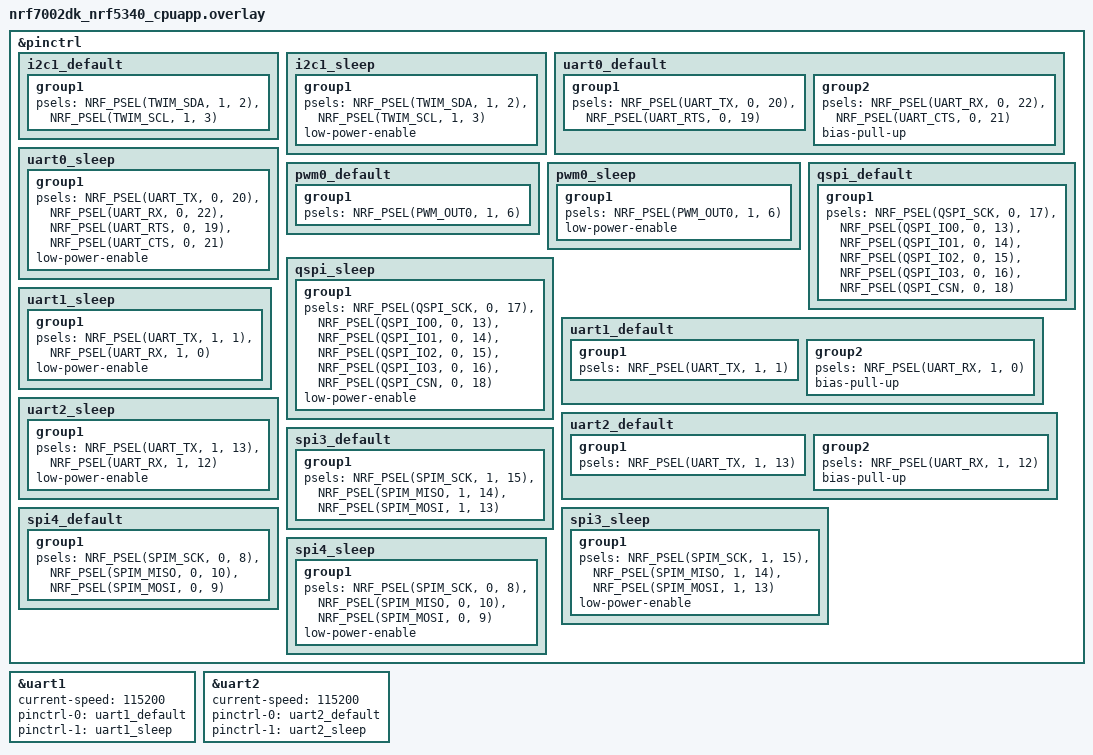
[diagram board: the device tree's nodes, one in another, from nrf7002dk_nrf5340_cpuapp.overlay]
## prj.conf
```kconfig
# Because we're not using console, and are using uart0 as hardware uart:
CONFIG_CONSOLE=n

# Logging
# CONFIG_PRINTK=y

CONFIG_UART_ASYNC_API=y
CONFIG_UART_INTERRUPT_DRIVEN=n

# So we can use k_malloc
CONFIG_HEAP_MEM_POOL_SIZE=2048
```

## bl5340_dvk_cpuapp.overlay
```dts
// Allow uart1 to be used as a normal UART instead of forwarding to network core for serial logging
/delete-node/ &gpio_fwd;


/ {
    chosen {
        /delete-property/ zephyr,keyboard-scan;
	};

    // aliases {
    //     /delete-property/ accel0;
    //     /delete-property/ bbram0;
    //     /delete-property/ kscan0;
    // };

    /delete-node/ aliases;

    /delete-node/ buttons;

    /delete-node/ leds;
};

// Just setting status of i2c1 to "disabled" doesn't work; causes error. Need to fully delete node.
/delete-node/ &i2c1;



&pinctrl {
    uart1_default: uart1_default {
		group1 {
			psels = <NRF_PSEL(UART_TX, 1, 1)>;
		};
		group2 {
			psels = <NRF_PSEL(UART_RX, 1, 0)>;
			bias-pull-up;
		};
	};

	uart1_sleep: uart1_sleep {
		group1 {
			psels = <NRF_PSEL(UART_TX, 1, 1)>,
				<NRF_PSEL(UART_RX, 1, 0)>;
			low-power-enable;
		};
	};

	uart2_default: uart2_default {
		group1 {
			psels = <NRF_PSEL(UART_TX, 1, 13)>;
		};
		group2 {
			psels = <NRF_PSEL(UART_RX, 1, 12)>;
			bias-pull-up;
		};
	};

	uart2_sleep: uart2_sleep {
		group1 {
			psels = <NRF_PSEL(UART_TX, 1, 13)>,
				<NRF_PSEL(UART_RX, 1, 12)>;
			low-power-enable;
		};
	};
};





&uart1 {
	status = "okay";
	current-speed = <115200>;
	pinctrl-0 = <&uart1_default>;
	pinctrl-1 = <&uart1_sleep>;
	pinctrl-names = "default", "sleep";
};

&uart2 {
	status = "okay";
	current-speed = <115200>;
	pinctrl-0 = <&uart2_default>;
	pinctrl-1 = <&uart2_sleep>;
	pinctrl-names = "default", "sleep";
};
```

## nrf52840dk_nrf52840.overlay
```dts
/ {
    chosen {
        /delete-property/ zephyr,console;
        /delete-property/ zephyr,shell-uart;
        /delete-property/ zephyr,uart-mcumgr;
        /delete-property/ zephyr,bt-mon-uart;
        /delete-property/ zephyr,bt-c2h-uart;
	};
};

&pinctrl {
    uart0_default: uart0_default {
		group1 {
			psels = <NRF_PSEL(UART_TX, 0, 28)>;
		};
		group2 {
			psels = <NRF_PSEL(UART_RX, 0, 30)>;
			bias-pull-up;
		};
	};

	uart0_sleep: uart0_sleep {
		group1 {
			psels = <NRF_PSEL(UART_TX, 0, 28)>,
				<NRF_PSEL(UART_RX, 0, 30)>;
			low-power-enable;
		};
	};

	uart1_default: uart1_default {
		group1 {
			psels = <NRF_PSEL(UART_TX, 0, 4)>;
            bias-pull-up;
		};
		group2 {
			psels = <NRF_PSEL(UART_RX, 0, 5)>;
			bias-pull-up;
		};
	};

	uart1_sleep: uart1_sleep {
		group1 {
			psels = <NRF_PSEL(UART_TX, 0, 4)>,
				<NRF_PSEL(UART_RX, 0, 5)>;
			low-power-enable;
		};
	};
};


&uart0 {
    compatible = "nordic,nrf-uarte";
	status = "okay";
    current-speed = <115200>;
	pinctrl-0 = <&uart0_default>;
	pinctrl-1 = <&uart0_sleep>;
	pinctrl-names = "default", "sleep";
};

&uart1 {
	status = "okay";
	current-speed = <9600>;
	pinctrl-0 = <&uart1_default>;
	pinctrl-1 = <&uart1_sleep>;
	pinctrl-names = "default", "sleep";
};
```

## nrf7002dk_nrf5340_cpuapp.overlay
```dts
// Allow uart1 to be used as a normal UART instead of forwarding to network core for serial logging
/delete-node/ &gpio_fwd;



&pinctrl {
	i2c1_default: i2c1_default {
		group1 {
			psels = <NRF_PSEL(TWIM_SDA, 1, 2)>,
				<NRF_PSEL(TWIM_SCL, 1, 3)>;
		};
	};

	i2c1_sleep: i2c1_sleep {
		group1 {
			psels = <NRF_PSEL(TWIM_SDA, 1, 2)>,
				<NRF_PSEL(TWIM_SCL, 1, 3)>;
			low-power-enable;
		};
	};

	uart0_default: uart0_default {
		group1 {
			psels = <NRF_PSEL(UART_TX, 0, 20)>,
				<NRF_PSEL(UART_RTS, 0, 19)>;
		};
		group2 {
			psels = <NRF_PSEL(UART_RX, 0, 22)>,
				<NRF_PSEL(UART_CTS, 0, 21)>;
			bias-pull-up;
		};
	};

	uart0_sleep: uart0_sleep {
		group1 {
			psels = <NRF_PSEL(UART_TX, 0, 20)>,
				<NRF_PSEL(UART_RX, 0, 22)>,
				<NRF_PSEL(UART_RTS, 0, 19)>,
				<NRF_PSEL(UART_CTS, 0, 21)>;
			low-power-enable;
		};
	};

	pwm0_default: pwm0_default {
		group1 {
			psels = <NRF_PSEL(PWM_OUT0, 1, 6)>;
		};
	};

	pwm0_sleep: pwm0_sleep {
		group1 {
			psels = <NRF_PSEL(PWM_OUT0, 1, 6)>;
			low-power-enable;
		};
	};

	qspi_default: qspi_default {
		group1 {
			psels = <NRF_PSEL(QSPI_SCK, 0, 17)>,
				<NRF_PSEL(QSPI_IO0, 0, 13)>,
				<NRF_PSEL(QSPI_IO1, 0, 14)>,
				<NRF_PSEL(QSPI_IO2, 0, 15)>,
				<NRF_PSEL(QSPI_IO3, 0, 16)>,
				<NRF_PSEL(QSPI_CSN, 0, 18)>;
		};
	};

	qspi_sleep: qspi_sleep {
		group1 {
			psels = <NRF_PSEL(QSPI_SCK, 0, 17)>,
				<NRF_PSEL(QSPI_IO0, 0, 13)>,
				<NRF_PSEL(QSPI_IO1, 0, 14)>,
				<NRF_PSEL(QSPI_IO2, 0, 15)>,
				<NRF_PSEL(QSPI_IO3, 0, 16)>,
				<NRF_PSEL(QSPI_CSN, 0, 18)>;
			low-power-enable;
		};
	};

    uart1_default: uart1_default {
		group1 {
			psels = <NRF_PSEL(UART_TX, 1, 1)>;
		};
		group2 {
			psels = <NRF_PSEL(UART_RX, 1, 0)>;
			bias-pull-up;
		};
	};

	uart1_sleep: uart1_sleep {
		group1 {
			psels = <NRF_PSEL(UART_TX, 1, 1)>,
				<NRF_PSEL(UART_RX, 1, 0)>;
			low-power-enable;
		};
	};

	uart2_default: uart2_default {
		group1 {
			psels = <NRF_PSEL(UART_TX, 1, 13)>;
		};
		group2 {
			psels = <NRF_PSEL(UART_RX, 1, 12)>;
			bias-pull-up;
		};
	};

	uart2_sleep: uart2_sleep {
		group1 {
			psels = <NRF_PSEL(UART_TX, 1, 13)>,
				<NRF_PSEL(UART_RX, 1, 12)>;
			low-power-enable;
		};
	};

	spi3_default: spi3_default {
		group1 {
			psels = <NRF_PSEL(SPIM_SCK, 1, 15)>,
				<NRF_PSEL(SPIM_MISO, 1, 14)>,
				<NRF_PSEL(SPIM_MOSI, 1, 13)>;
		};
	};

	spi3_sleep: spi3_sleep {
		group1 {
			psels = <NRF_PSEL(SPIM_SCK, 1, 15)>,
				<NRF_PSEL(SPIM_MISO, 1, 14)>,
				<NRF_PSEL(SPIM_MOSI, 1, 13)>;
			low-power-enable;
		};
	};

	spi4_default: spi4_default {
		group1 {
			psels = <NRF_PSEL(SPIM_SCK, 0, 8)>,
				<NRF_PSEL(SPIM_MISO, 0, 10)>,
				<NRF_PSEL(SPIM_MOSI, 0, 9)>;
		};
	};

	spi4_sleep: spi4_sleep {
		group1 {
			psels = <NRF_PSEL(SPIM_SCK, 0, 8)>,
				<NRF_PSEL(SPIM_MISO, 0, 10)>,
				<NRF_PSEL(SPIM_MOSI, 0, 9)>;
			low-power-enable;
		};
	};

};





&uart1 {
	status = "okay";
	current-speed = <115200>;
	pinctrl-0 = <&uart1_default>;
	pinctrl-1 = <&uart1_sleep>;
	pinctrl-names = "default", "sleep";
};

&uart2 {
	status = "okay";
	current-speed = <115200>;
	pinctrl-0 = <&uart2_default>;
	pinctrl-1 = <&uart2_sleep>;
	pinctrl-names = "default", "sleep";
};
```

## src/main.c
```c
#include <zephyr/kernel.h>
#include <zephyr/drivers/gpio.h>
#include <zephyr/drivers/i2c.h>
#include <zephyr/sys/printk.h>
#include <zephyr/drivers/uart.h>

#include <string.h>  // For memset

/**
 * This program reads data over uart1, then prints the receved data along with debug info
 * to uart0 with.
 */

#define DEBUG_PRINT_ENABLED 1

const struct device *gps_uart = DEVICE_DT_GET(DT_NODELABEL(uart1));  // uart1: TX = P0.04, RX = P0.05.    TO BE USED FOR UART COMMS WITH GPS
const struct device *dbg_uart = DEVICE_DT_GET(DT_NODELABEL(uart0));  // uart0: TX = P0.28, RX = P0.30.    TO BE USED FOR UART DEBUGGING

#define BUFF_SIZE 50  // Note: UART_RX_RDY event only occurs when RX buffer is full.
static char* rx_buf;  // Buffer that is used internally by UART callback


static void dbg_print(char* buf, int len) {
	/**
	 * Helper function to print things over debug uart
 	 */
	if (DEBUG_PRINT_ENABLED) {
		uart_tx(dbg_uart, buf, len, SYS_FOREVER_US);
	}
}


void handle_uart_rx_data(struct uart_event *evt) {
	/**
	 * Parse string received over UART and store important info. 
	 * 
	 * IMPORTANT: THIS IS CALLED INSIDE OF gps_uart_cb SO WE CANNOT DEBUG PRINT HERE
  	 */
	for (int i=0; i < evt->data.rx.len; i++) {
		// dbg_print(&(evt->data.rx.buf[evt->data.rx.offset + i]), 1);
	}
}


static void gps_uart_cb(const struct device *dev, struct uart_event *evt, void *user_data) {
	/**
	 * IMPORTANT: DEBUG PRINTS INSIDE THE UART CALLBACK FUNCTION WILL CASE THE FUNCTION TO RETURN
 	 */

	int ret;

	switch (evt->type) {
		case UART_RX_RDY:
			handle_uart_rx_data(evt);
			break;
		case UART_RX_BUF_REQUEST:
			rx_buf = k_malloc(BUFF_SIZE * sizeof(uint8_t));
			if (rx_buf) {
				ret = uart_rx_buf_rsp(gps_uart, rx_buf, BUFF_SIZE);
				if (ret) { 
					dbg_print("uart_rx_buf_rsp failed.", sizeof("uart_rx_buf_rsp failed."));
				}
			} else {
				dbg_print("Not able to allocate UART receive buffer.", sizeof("Not able to allocate UART receive buffer."));
			}
			break;
		case UART_RX_BUF_RELEASED:
			k_free(rx_buf);
			break;
		case UART_RX_DISABLED:
			ret = uart_rx_enable(gps_uart, rx_buf, BUFF_SIZE, SYS_FOREVER_US);
			if (ret) { 
				dbg_print("uart_rx_enable failed.", sizeof("uart_rx_enable failed."));
			}
			break;
		case UART_RX_STOPPED:
			break;
		default:
			break;
	}
}


static void dbg_uart_cb(const struct device *dev, struct uart_event *evt, void *user_data) { }  // No need to do anything


int main(void) {

	k_msleep(1000);
	int ret;

	/////////////////////////////////// DEBUG UART SETUP ///////////////////////////////////
	if (!device_is_ready(dbg_uart)) {
		return -1;
	}

	ret = uart_callback_set(dbg_uart, dbg_uart_cb, NULL);
	if (ret) {
		return ret;
	}

	/////////////////////////////////// GPS UART SETUP ///////////////////////////////////
	if (!device_is_ready(gps_uart)) {
		dbg_print("gps_uart not ready.", sizeof("gps_uart not ready."));
		return -1;
	}

	ret = uart_callback_set(gps_uart, gps_uart_cb, NULL);
	if (ret) {
		dbg_print("gps_uart_cb set failed.", sizeof("gps_uart_cb set failed."));
		return ret;
	}

	k_msleep(1000);
	ret = uart_rx_enable(gps_uart, rx_buf, BUFF_SIZE, SYS_FOREVER_US);
	if (ret) {
		dbg_print("gps_uart uart_rx_enable failed.", sizeof("gps_uart uart_rx_enable failed."));
		return ret;
	}

	/////////////////////////////////// MAIN LOOP ///////////////////////////////////
	int ctr = 0;
	while (1) {
		ctr++;
		k_msleep(250);
	}

	return 0;
}
```
